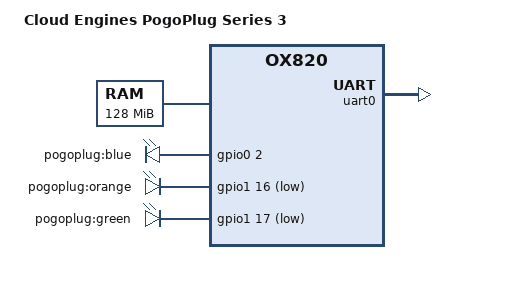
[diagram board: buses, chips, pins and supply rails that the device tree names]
/*
 * cloudengines-pogoplug-series-3.dtsi - Device tree file for Cloud Engines PogoPlug Series 3
 *
 * Copyright (C) 2016 Neil Armstrong <narmstrong@baylibre.com>
 *
 * Licensed under GPLv2 or later
 */

/dts-v1/;
#include "ox820.dtsi"

/ {
	model = "Cloud Engines PogoPlug Series 3";

	compatible = "cloudengines,pogoplugv3", "oxsemi,ox820";

	chosen {
		bootargs = "console=ttyS0,115200n8 earlyprintk=serial";
	};

	memory {
		/* 128Mbytes DDR */
		reg = <0x60000000 0x8000000>;
	};

	aliases {
		serial0 = &uart0;
		gpio0 = &gpio0;
		gpio1 = &gpio1;
	};

	leds {
		compatible = "gpio-leds";

		blue {
			label = "pogoplug:blue";
			gpios = <&gpio0 2 0>;
			default-state = "keep";
		};

		orange {
			label = "pogoplug:orange";
			gpios = <&gpio1 16 1>;
			default-state = "keep";
		};

		green {
			label = "pogoplug:green";
			gpios = <&gpio1 17 1>;
			default-state = "keep";
		};
	};
};

&uart0 {
	status = "okay";

	pinctrl-names = "default";
	pinctrl-0 = <&pinctrl_uart0>;
};
